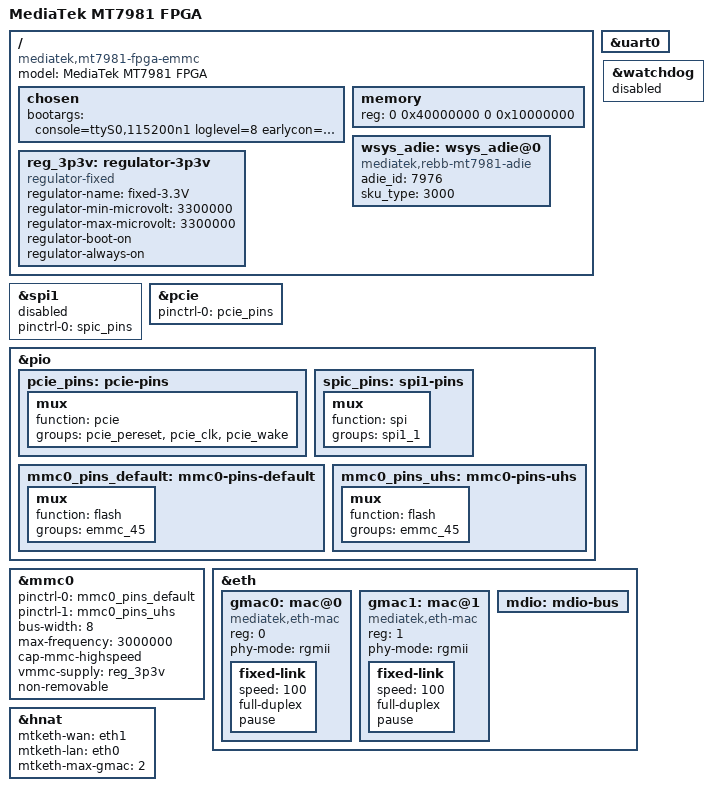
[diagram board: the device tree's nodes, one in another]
/dts-v1/;
#include "mt7981-fpga.dtsi"
/ {
	model = "MediaTek MT7981 FPGA";
	compatible = "mediatek,mt7981-fpga-emmc";
	chosen {
		bootargs = "console=ttyS0,115200n1 loglevel=8  \
				earlycon=uart8250,mmio32,0x11002000 \
				root=PARTLABEL=rootfs rootfstype=squashfs,f2fs";
	};

	memory {
		// fpga ddr2: 128MB*2
		reg = <0 0x40000000 0 0x10000000>;
	};

	wsys_adie: wsys_adie@0 {
	// fpga cases need to manual change adie_id / sku_type for dvt only
		compatible = "mediatek,rebb-mt7981-adie";
		adie_id = <7976>;
		sku_type = <3000>;
	};

	reg_3p3v: regulator-3p3v {
		compatible = "regulator-fixed";
		regulator-name = "fixed-3.3V";
		regulator-min-microvolt = <3300000>;
		regulator-max-microvolt = <3300000>;
		regulator-boot-on;
		regulator-always-on;
	};
};

&uart0 {
	status = "okay";
};

&spi1 {
	pinctrl-names = "default";
	/* pin shared with snfi */
	pinctrl-0 = <&spic_pins>;
	status = "disabled";
};

&pcie {
	pinctrl-names = "default";
	pinctrl-0 = <&pcie_pins>;
	status = "okay";
};

&pio {
	pcie_pins: pcie-pins {
		mux {
			function = "pcie";
			groups = "pcie_pereset", "pcie_clk", "pcie_wake";
		};
	};

	spic_pins: spi1-pins {
		mux {
			function = "spi";
			groups = "spi1_1";
		};
	};

	mmc0_pins_default: mmc0-pins-default {
		mux {
			function = "flash";
			groups = "emmc_45";
		};
	};

	mmc0_pins_uhs: mmc0-pins-uhs {
		mux {
			function = "flash";
			groups = "emmc_45";
		};
	};
};

&watchdog {
	status = "disabled";
};

&mmc0 {
	pinctrl-names = "default", "state_uhs";
	pinctrl-0 = <&mmc0_pins_default>;
	pinctrl-1 = <&mmc0_pins_uhs>;
	bus-width = <8>;
	max-frequency = <3000000>;
	cap-mmc-highspeed;
	vmmc-supply = <&reg_3p3v>;
	non-removable;
	status = "okay";
};

&eth {
	status = "okay";

	gmac0: mac@0 {
		compatible = "mediatek,eth-mac";
		reg = <0>;
		phy-mode = "rgmii";

		fixed-link {
			speed = <100>;
			full-duplex;
			pause;
		};
	};

	gmac1: mac@1 {
		compatible = "mediatek,eth-mac";
		reg = <1>;
		phy-mode = "rgmii";

		fixed-link {
			speed = <100>;
			full-duplex;
			pause;
		};
	};

	mdio: mdio-bus {
		#address-cells = <1>;
		#size-cells = <0>;
	};
};

&hnat {
	mtketh-wan = "eth1";
	mtketh-lan = "eth0";
	mtketh-max-gmac = <2>;
	status = "okay";
};
